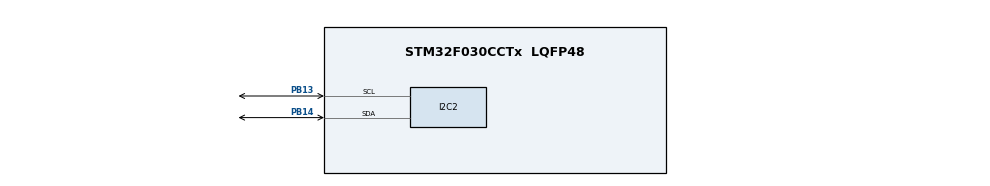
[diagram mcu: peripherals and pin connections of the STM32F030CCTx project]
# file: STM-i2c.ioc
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Mcu.Family=STM32F0
Mcu.Name=STM32F030CCTx
Mcu.Package=LQFP48
NVIC.I2C2_IRQn=true\:0\:0\:false\:false\:true\:true
PB13.Mode=I2C
PB13.Signal=I2C2_SCL
PB14.Mode=I2C
PB14.Signal=I2C2_SDA
ProjectManager.HeapSize=0x200
ProjectManager.StackSize=0x400
ProjectManager.TargetToolchain=SW4STM32
board=STM-i2c

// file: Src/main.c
/**
  ******************************************************************************
  * @file           : main.c
  * @brief          : Main program body
  ******************************************************************************
  ** This notice applies to any and all portions of this file
  * that are not between comment pairs USER CODE BEGIN and
  * USER CODE END. Other portions of this file, whether
  * inserted by the user or by software development tools
  * are owned by their respective copyright owners.
  *
  * COPYRIGHT(c) 2018 STMicroelectronics
  *
  * Redistribution and use in source and binary forms, with or without modification,
  * are permitted provided that the following conditions are met:
  *   1. Redistributions of source code must retain the above copyright notice,
  *      this list of conditions and the following disclaimer.
  *   2. Redistributions in binary form must reproduce the above copyright notice,
  *      this list of conditions and the following disclaimer in the documentation
  *      and/or other materials provided with the distribution.
  *   3. Neither the name of STMicroelectronics nor the names of its contributors
  *      may be used to endorse or promote products derived from this software
  *      without specific prior written permission.
  *
  * THIS SOFTWARE IS PROVIDED BY THE COPYRIGHT HOLDERS AND CONTRIBUTORS "AS IS"
  * AND ANY EXPRESS OR IMPLIED WARRANTIES, INCLUDING, BUT NOT LIMITED TO, THE
  * IMPLIED WARRANTIES OF MERCHANTABILITY AND FITNESS FOR A PARTICULAR PURPOSE ARE
  * DISCLAIMED. IN NO EVENT SHALL THE COPYRIGHT HOLDER OR CONTRIBUTORS BE LIABLE
  * FOR ANY DIRECT, INDIRECT, INCIDENTAL, SPECIAL, EXEMPLARY, OR CONSEQUENTIAL
  * DAMAGES (INCLUDING, BUT NOT LIMITED TO, PROCUREMENT OF SUBSTITUTE GOODS OR
  * SERVICES; LOSS OF USE, DATA, OR PROFITS; OR BUSINESS INTERRUPTION) HOWEVER
  * CAUSED AND ON ANY THEORY OF LIABILITY, WHETHER IN CONTRACT, STRICT LIABILITY,
  * OR TORT (INCLUDING NEGLIGENCE OR OTHERWISE) ARISING IN ANY WAY OUT OF THE USE
  * OF THIS SOFTWARE, EVEN IF ADVISED OF THE POSSIBILITY OF SUCH DAMAGE.
  *
  ******************************************************************************
  */
#include "main.h"
#include "stm32f0xx_hal.h"
#include  "inttypes.h"

/* USER CODE BEGIN Includes */
#define mcp_addr       0x18 //adress of temp
#define mcp_reg_conf   0x01
#define reg_temp       0x30
/* USER CODE END Includes */

I2C_HandleTypeDef hi2c2;

uint8_t data_write[3];
uint8_t data_read[2];

/* USER CODE BEGIN PV */
/* Private variables ---------------------------------------------------------*/

/* USER CODE END PV */

void SystemClock_Config(void);
static void MX_GPIO_Init(void);
static void MX_I2C2_Init(void);

/* USER CODE BEGIN PFP */
/* Private function prototypes -----------------------------------------------*/

/* USER CODE END PFP */

int main(void)
{

  /* MCU Configuration----------------------------------------------------------*/

  /* Reset of all peripherals, Initializes the Flash interface and the Systick. */
  HAL_Init();

  /* Configure the system clock */
  SystemClock_Config();

  /* Initialize all configured peripherals */
  MX_GPIO_Init();
  MX_I2C2_Init();
  /* USER CODE BEGIN 2 */

  int tempval;
  data_write[0] = mcp_reg_conf;
  data_write[1] = 0x00;  // config msb
  data_write[2] = 0x00;  // config lsb

  HAL_I2C_Master_Transmit(&hi2c2,0x18<<1,data_write,3,100);

  data_write[0]= 0x05;
  /* USER CODE END 2 */

  /* Infinite loop */
  /* USER CODE BEGIN WHILE */
  while (1)
  {
	  HAL_I2C_Master_Transmit(&hi2c2,0x18<<1,data_write,1,100);
	  for (uint16_t y;y<10000;y++);
	  HAL_I2C_Master_Receive(&hi2c2,0x18<<1,data_read,2,100);

	   if((data_read[0] & 0x80)  == 0x80) {

	        }
	        if((data_read[0] & 0x40) == 0x40) {

	        }
	        if((data_read[0] & 0x20) == 0x20) {

	        }
	        if(data_read[0] & 0xE0) {
	            data_read[0] = data_read[0] & 0x1F;  // clear flag bits
	        }
	        if((data_read[0] & 0x10) == 0x10) {
	            data_read[0] = data_read[0] & 0x0F;
	            tempval = 256 - (data_read[0] << 4) + (data_read[1] >> 4);
	        }
	        else {
	                   tempval = (data_read[0] << 4) + (data_read[1] >> 4);
	               }

  }
  /* USER CODE END 3 */

}

void SystemClock_Config(void)
{

  RCC_OscInitTypeDef RCC_OscInitStruct;
  RCC_ClkInitTypeDef RCC_ClkInitStruct;

    /**Initializes the CPU, AHB and APB busses clocks
    */
  RCC_OscInitStruct.OscillatorType = RCC_OSCILLATORTYPE_HSI;
  RCC_OscInitStruct.HSIState = RCC_HSI_ON;
  RCC_OscInitStruct.HSICalibrationValue = 16;
  RCC_OscInitStruct.PLL.PLLState = RCC_PLL_NONE;
  if (HAL_RCC_OscConfig(&RCC_OscInitStruct) != HAL_OK)
  {
    _Error_Handler(__FILE__, __LINE__);
  }

    /**Initializes the CPU, AHB and APB busses clocks
    */
  RCC_ClkInitStruct.ClockType = RCC_CLOCKTYPE_HCLK|RCC_CLOCKTYPE_SYSCLK
                              |RCC_CLOCKTYPE_PCLK1;
  RCC_ClkInitStruct.SYSCLKSource = RCC_SYSCLKSOURCE_HSI;
  RCC_ClkInitStruct.AHBCLKDivider = RCC_SYSCLK_DIV1;
  RCC_ClkInitStruct.APB1CLKDivider = RCC_HCLK_DIV1;

  if (HAL_RCC_ClockConfig(&RCC_ClkInitStruct, FLASH_LATENCY_0) != HAL_OK)
  {
    _Error_Handler(__FILE__, __LINE__);
  }

    /**Configure the Systick interrupt time
    */
  HAL_SYSTICK_Config(HAL_RCC_GetHCLKFreq()/1000);

    /**Configure the Systick
    */
  HAL_SYSTICK_CLKSourceConfig(SYSTICK_CLKSOURCE_HCLK);

  /* SysTick_IRQn interrupt configuration */
  HAL_NVIC_SetPriority(SysTick_IRQn, 0, 0);
}

/* I2C2 init function */
static void MX_I2C2_Init(void)
{

  hi2c2.Instance = I2C2;
  hi2c2.Init.Timing = 0x2000090E;
  hi2c2.Init.OwnAddress1 = 0;
  hi2c2.Init.AddressingMode = I2C_ADDRESSINGMODE_7BIT;
  hi2c2.Init.DualAddressMode = I2C_DUALADDRESS_DISABLE;
  hi2c2.Init.OwnAddress2 = 0;
  hi2c2.Init.OwnAddress2Masks = I2C_OA2_NOMASK;
  hi2c2.Init.GeneralCallMode = I2C_GENERALCALL_DISABLE;
  hi2c2.Init.NoStretchMode = I2C_NOSTRETCH_DISABLE;
  if (HAL_I2C_Init(&hi2c2) != HAL_OK)
  {
    _Error_Handler(__FILE__, __LINE__);
  }

    /**Configure Analogue filter
    */
  if (HAL_I2CEx_ConfigAnalogFilter(&hi2c2, I2C_ANALOGFILTER_ENABLE) != HAL_OK)
  {
    _Error_Handler(__FILE__, __LINE__);
  }

    /**Configure Digital filter
    */
  if (HAL_I2CEx_ConfigDigitalFilter(&hi2c2, 0) != HAL_OK)
  {
    _Error_Handler(__FILE__, __LINE__);
  }

}

/** Pinout Configuration
*/
static void MX_GPIO_Init(void)
{

  /* GPIO Ports Clock Enable */
  __HAL_RCC_GPIOB_CLK_ENABLE();

}

void _Error_Handler(char *file, int line)
{
  while(1)
  {
  }
}

/************************ (C) COPYRIGHT STMicroelectronics *****END OF FILE****/
